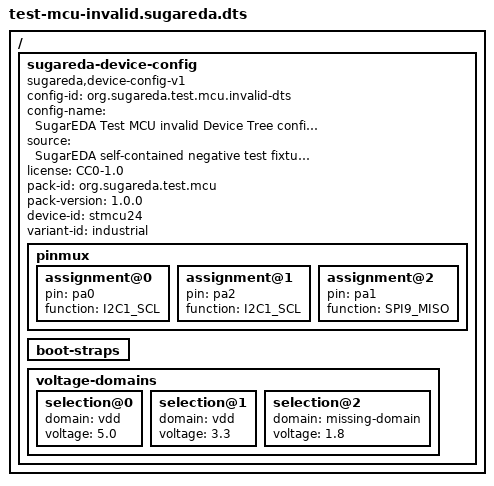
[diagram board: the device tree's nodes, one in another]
/dts-v1/;

/ {
  sugareda-device-config {
    compatible = "sugareda,device-config-v1";
    config-id = "org.sugareda.test.mcu.invalid-dts";
    config-name = "SugarEDA Test MCU invalid Device Tree configuration";
    source = "SugarEDA self-contained negative test fixture; fictional data only";
    license = "CC0-1.0";
    pack-id = "org.sugareda.test.mcu";
    pack-version = "1.0.0";
    device-id = "stmcu24";
    variant-id = "industrial";

    pinmux {
      assignment@0 { pin = "pa0"; function = "I2C1_SCL"; };
      assignment@1 { pin = "pa2"; function = "I2C1_SCL"; };
      assignment@2 { pin = "pa1"; function = "SPI9_MISO"; };
    };

    boot-straps {
    };

    voltage-domains {
      selection@0 { domain = "vdd"; voltage = "5.0"; };
      selection@1 { domain = "vdd"; voltage = "3.3"; };
      selection@2 { domain = "missing-domain"; voltage = "1.8"; };
    };
  };
};
